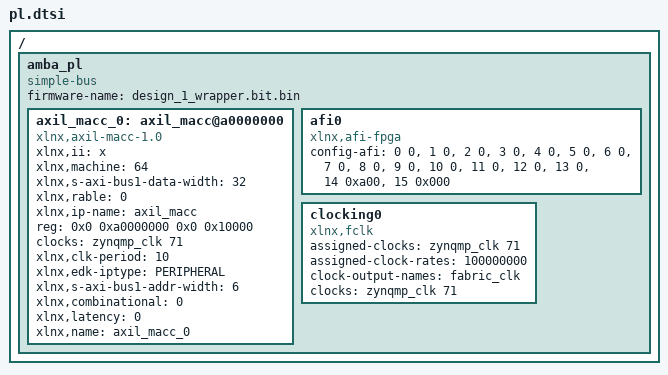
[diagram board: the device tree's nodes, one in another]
/ {
	amba_pl: amba_pl {
		ranges;
		compatible = "simple-bus";
		#address-cells = <2>;
		#size-cells = <2>;
		firmware-name = "design_1_wrapper.bit.bin";
		axil_macc_0: axil_macc@a0000000 {
			compatible = "xlnx,axil-macc-1.0";
			xlnx,ii = "x";
			xlnx,machine = <64>;
			xlnx,s-axi-bus1-data-width = <32>;
			xlnx,rable = <0>;
			xlnx,ip-name = "axil_macc";
			reg = <0x0 0xa0000000 0x0 0x10000>;
			clocks = <&zynqmp_clk 71>;
			xlnx,clk-period = <10>;
			xlnx,edk-iptype = "PERIPHERAL";
			status = "okay";
			clock-names = "ap_clk";
			xlnx,s-axi-bus1-addr-width = <6>;
			xlnx,combinational = <0>;
			xlnx,latency = <0>;
			xlnx,name = "axil_macc_0";
		};
		afi0: afi0 {
			status = "okay";
			compatible = "xlnx,afi-fpga";
			config-afi = < 0 0>, <1 0>, <2 0>, <3 0>, <4 0>, <5 0>, <6 0>, <7 0>, <8 0>, <9 0>, <10 0>, <11 0>, <12 0>, <13 0>, <14 0xa00>, <15 0x000>;
		};
		clocking0: clocking0 {
			compatible = "xlnx,fclk";
			assigned-clocks = <&zynqmp_clk 71>;
			assigned-clock-rates = <100000000>;
			#clock-cells = <0>;
			clock-output-names = "fabric_clk";
			clocks = <&zynqmp_clk 71>;
		};
	};
};
